AUTOSAR XML (schema 00050)
package /ComponentTypes
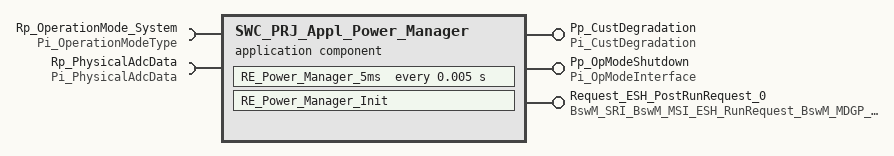
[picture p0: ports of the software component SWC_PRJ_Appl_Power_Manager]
  application sw component type SWC_PRJ_Appl_Power_Manager
    provide port Pp_CustDegradation: nonqueued-sender-com-spec{data-element=De_CustDegradation, init-value=constant-reference=C_CustDegradation}, provided-interface=Pi_CustDegradation
    provide port Pp_OpModeShutdown: nonqueued-sender-com-spec{data-element=De_OpModeShutdown, init-value=constant-reference=C_OpModeShutdown_init_T}, provided-interface=Pi_OpModeInterface
    require port Rp_OperationMode_System: nonqueued-receiver-com-spec{data-element=De_OperationMode_System, filter=data-filter-type=ALWAYS, init-value=0}, required-interface=Pi_OperationModeType
    require port Rp_PhysicalAdcData: nonqueued-receiver-com-spec{data-element=De_PhysicalAdcData, filter=data-filter-type=ALWAYS, init-value=fields=[Adc_Board_Rev:0, Adc_Batt_Volt:0, Adc_Pos_Gnd_A:0, Adc_Pos_Gnd_B:0, Adc_Pos_Gnd_C:0, Adc_Pos_Gnd_D:0, Adc_Eth_0v9:0, Adc_Rdi_Detect:0, Adc_MMIC_Temp:0, Adc_Mcu_Temp:0, Validity_Flag:0]}, required-interface=Pi_PhysicalAdcData
    provide port Request_ESH_PostRunRequest_0: nonqueued-sender-com-spec=data-element=requestedMode, provided-interface=BswM_SRI_BswM_MSI_ESH_RunRequest_BswM_MDGP_ESH_RunRequest
    behavior SWC_PRJ_Appl_Power_Manager_InternalBehavior: handle-termination-and-restart=NO-SUPPORT
      init event SWC_PRJ_Appl_Power_Manager_InitEvent: start-on-event=RE_Power_Manager_Init
      timing event TMT_RE_Power_Manager_5ms: start-on-event=RE_Power_Manager_5ms, period=0.005
      runnable RE_Power_Manager_Init
        data-receive-point-by-arguments:
          access REC_Rp_PhysicalAdcData_De_PhysicalAdcData: accessed-variable=Rp_PhysicalAdcData.De_PhysicalAdcData
        data-send-points:
          access SEND_Pp_CustDegradation_De_CustDegradation: accessed-variable=Pp_CustDegradation.De_CustDegradation
          access SEND_Request_ESH_PostRunRequest_0_requestedMode: accessed-variable=Request_ESH_PostRunRequest_0.requestedMode
      runnable RE_Power_Manager_5ms
        data-receive-point-by-arguments:
          access REC_Rp_OperationMode_System_De_OperationMode_System: accessed-variable=Rp_OperationMode_System.De_OperationMode_System
          access REC_Rp_PhysicalAdcData_De_PhysicalAdcData: accessed-variable=Rp_PhysicalAdcData.De_PhysicalAdcData
        data-send-points:
          access SEND_Pp_OpModeShutdown_De_OpModeShutdown: accessed-variable=Pp_OpModeShutdown.De_OpModeShutdown
          access SEND_Pp_CustDegradation_De_CustDegradation: accessed-variable=Pp_CustDegradation.De_CustDegradation
          access SEND_Request_ESH_PostRunRequest_0_requestedMode: accessed-variable=Request_ESH_PostRunRequest_0.requestedMode
  swc implementation SWC_PRJ_Appl_Power_Manager_Implementation: behavior=SWC_PRJ_Appl_Power_Manager_InternalBehavior
